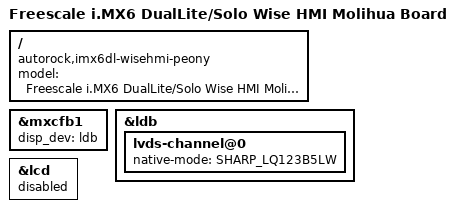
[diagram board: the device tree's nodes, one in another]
/dts-v1/;

#include "imx6dl.dtsi"
#include "imx6qdl-wisehmi-dev.dtsi"

/ {
	model = "Freescale i.MX6 DualLite/Solo Wise HMI Molihua Board";
	compatible = "autorock,imx6dl-wisehmi-peony", "autorock,imx6qdl-wisehmi", "fsl,imx6dl";
};

&mxcfb1 {
	disp_dev = "ldb";
/*	interface_pix_fmt = "RGB24";*/
};

&ldb {
	status = "okay";
	lvds-channel@0 {
		native-mode = <&SHARP_LQ123B5LW>;
	};
};

&lcd {
	status = "disabled";
};

